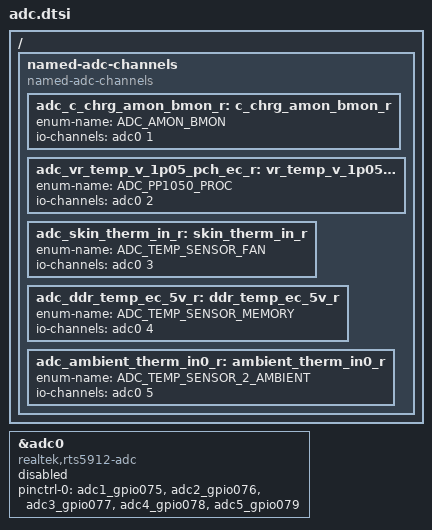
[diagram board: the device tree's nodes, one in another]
/* Copyright 2024 The ChromiumOS Authors
 * Use of this source code is governed by a BSD-style license that can be
 * found in the LICENSE file.
 */

/ {
	named-adc-channels {
		compatible = "named-adc-channels";

		adc_c_chrg_amon_bmon_r: c_chrg_amon_bmon_r {
			enum-name = "ADC_AMON_BMON";
			io-channels = <&adc0 1>;
		};
		adc_vr_temp_v_1p05_pch_ec_r: vr_temp_v_1p05_pch_ec_r {
			enum-name = "ADC_PP1050_PROC";
			io-channels = <&adc0 2>;
		};
		adc_skin_therm_in_r: skin_therm_in_r {
			enum-name = "ADC_TEMP_SENSOR_FAN";
			io-channels = <&adc0 3>;
		};
		adc_ddr_temp_ec_5v_r: ddr_temp_ec_5v_r {
			enum-name = "ADC_TEMP_SENSOR_MEMORY";
			io-channels = <&adc0 4>;
		};
		adc_ambient_therm_in0_r: ambient_therm_in0_r {
			enum-name = "ADC_TEMP_SENSOR_2_AMBIENT";
			io-channels = <&adc0 5>;
		};
	};
};

&adc0 {
	compatible = "realtek,rts5912-adc";
	pinctrl-0 = <&adc1_gpio075
		&adc2_gpio076
		&adc3_gpio077
		&adc4_gpio078
		&adc5_gpio079
	>;
	pinctrl-names = "default";
	status = "disabled";
};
